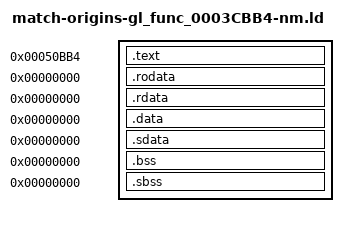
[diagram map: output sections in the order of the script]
/* Standard linker bindings; original USO identity is independently audited. */
SECTIONS {
 .text 0x50bb4 : SUBALIGN(4) { *(.text) *(.text.*) }
 .rodata 0x0 : SUBALIGN(4) { *(.rodata) *(.rodata.*) }
 .rdata 0x0 : SUBALIGN(4) { *(.rdata) *(.rdata.*) }
 .data 0x0 : SUBALIGN(4) { *(.data) *(.data.*) }
 .sdata 0x0 : SUBALIGN(4) { *(.sdata) *(.sdata.*) }
 .bss 0x0 : SUBALIGN(4) { *(.bss) *(.bss.*) }
 .sbss 0x0 : SUBALIGN(4) { *(.sbss) *(.sbss.*) }
 /DISCARD/ : { *(.mdebug) *(.reginfo) *(.pdr) *(.comment) *(.MIPS.abiflags) *(.options) }
}
gl_3cbb4_magnitude_5bbcc = 0x0;
gl_3cbb4_normalize_5c9bc = 0x0;
gl_3cbb4_segment_3a58c = 0x0;
